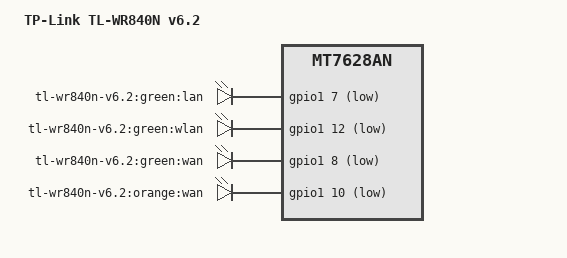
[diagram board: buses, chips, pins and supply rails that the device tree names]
#include "TL-WR840NV6.x.dtsi"

/ {
	compatible = "tplink,tl-wr840n-v6.2", "mediatek,mt7628an-soc";
	model = "TP-Link TL-WR840N v6.2";

	leds {
		compatible = "gpio-leds";

		lan {
			label = "tl-wr840n-v6.2:green:lan";
			gpios = <&gpio1 7 GPIO_ACTIVE_LOW>;
		};

		wlan {
			label = "tl-wr840n-v6.2:green:wlan";
			gpios = <&gpio1 12 GPIO_ACTIVE_LOW>;
		};

		led_power_green: wan {
			label = "tl-wr840n-v6.2:green:wan";
			gpios = <&gpio1 8 GPIO_ACTIVE_LOW>;
		};

		led_power_orange: power {
			label = "tl-wr840n-v6.2:orange:wan";
			gpios = <&gpio1 10 GPIO_ACTIVE_LOW>;
		};
	};
};

&ethernet {
	mtd-mac-address-increment = <1>;
};

&ralinkgpio {
	ralink,group = "p1led_an", "p3led_an", "p4led_an", "perst";
};
